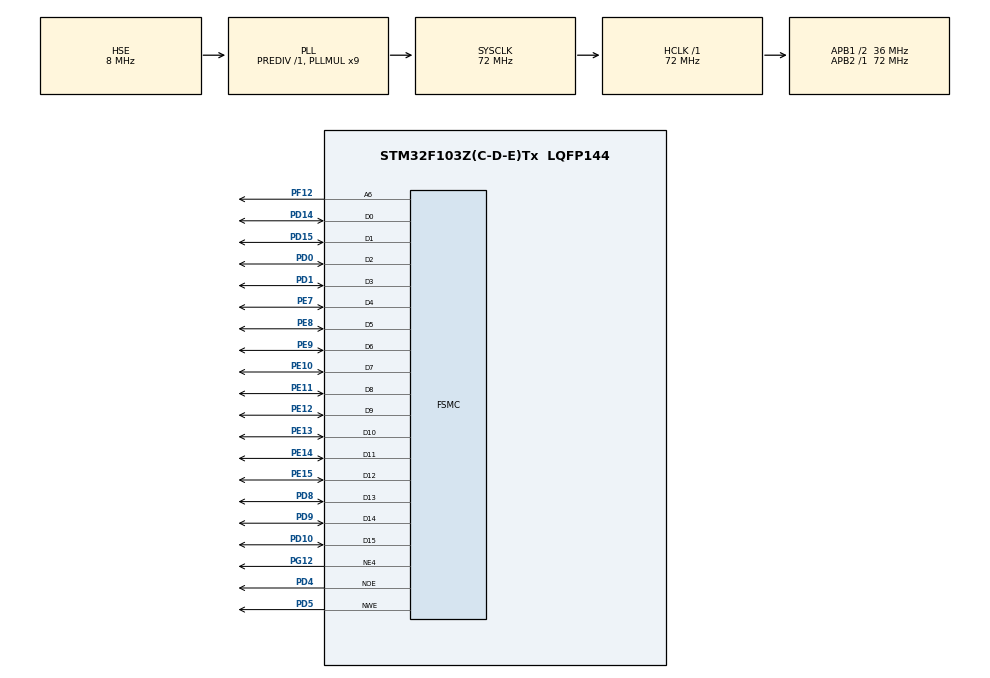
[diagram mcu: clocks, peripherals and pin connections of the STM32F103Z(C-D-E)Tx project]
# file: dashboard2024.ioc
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FREERTOS.Tasks01=defaultTask,24,128,StartDefaultTask,Default,NULL,Dynamic,NULL,NULL
FSMC.BusTurnAroundDuration4=0
FSMC.DataSetupTime4=60
FSMC.ExtendedAddressSetupTime4=9
FSMC.ExtendedBusTurnAroundDuration4=0
FSMC.ExtendedDataSetupTime4=8
FSMC.ExtendedMode4=FSMC_EXTENDED_MODE_ENABLE
Mcu.Family=STM32F1
Mcu.Name=STM32F103Z(C-D-E)Tx
Mcu.Package=LQFP144
NVIC.PriorityGroup=NVIC_PRIORITYGROUP_4
NVIC.TIM4_IRQn=true\:15\:0\:false\:false\:true\:false\:false\:true\:true
NVIC.TimeBase=TIM4_IRQn
NVIC.TimeBaseIP=TIM4
OSC_IN.Mode=HSE-External-Oscillator
OSC_IN.Signal=RCC_OSC_IN
OSC_OUT.Mode=HSE-External-Oscillator
OSC_OUT.Signal=RCC_OSC_OUT
PA13.Mode=Serial_Wire
PA13.Signal=SYS_JTMS-SWDIO
PA14.Mode=Serial_Wire
PA14.Signal=SYS_JTCK-SWCLK
PD0.Signal=FSMC_D2_DA2
PD1.Signal=FSMC_D3_DA3
PD10.Signal=FSMC_D15_DA15
PD14.Signal=FSMC_D0_DA0
PD15.Signal=FSMC_D1_DA1
PD4.Signal=FSMC_NOE
PD5.Signal=FSMC_NWE
PD8.Signal=FSMC_D13_DA13
PD9.Signal=FSMC_D14_DA14
PE10.Signal=FSMC_D7_DA7
PE11.Signal=FSMC_D8_DA8
PE12.Signal=FSMC_D9_DA9
PE13.Signal=FSMC_D10_DA10
PE14.Signal=FSMC_D11_DA11
PE15.Signal=FSMC_D12_DA12
PE7.Signal=FSMC_D4_DA4
PE8.Signal=FSMC_D5_DA5
PE9.Signal=FSMC_D6_DA6
PF12.Signal=FSMC_A6
PG12.Mode=NorPsramChipSelect4_4
PG12.Signal=FSMC_NE4
ProjectManager.HeapSize=0x200
ProjectManager.StackSize=0x400
ProjectManager.TargetToolchain=MDK-ARM V5.32
RCC.AHBFreq_Value=72000000
RCC.APB1CLKDivider=RCC_HCLK_DIV2
RCC.APB1Freq_Value=36000000
RCC.APB1TimFreq_Value=72000000
RCC.APB2Freq_Value=72000000
RCC.APB2TimFreq_Value=72000000
RCC.HCLKFreq_Value=72000000
RCC.PLLMUL=RCC_PLL_MUL9
RCC.PLLSourceVirtual=RCC_PLLSOURCE_HSE
RCC.SYSCLKFreq_VALUE=72000000
RCC.SYSCLKSource=RCC_SYSCLKSOURCE_PLLCLK
RCC.USBFreq_Value=72000000
SH.FSMC_A6.0=FSMC_A6,A6_4
SH.FSMC_D0_DA0.0=FSMC_D0,16b-d4
SH.FSMC_D10_DA10.0=FSMC_D10,16b-d4
SH.FSMC_D11_DA11.0=FSMC_D11,16b-d4
SH.FSMC_D12_DA12.0=FSMC_D12,16b-d4
SH.FSMC_D13_DA13.0=FSMC_D13,16b-d4
SH.FSMC_D14_DA14.0=FSMC_D14,16b-d4
SH.FSMC_D15_DA15.0=FSMC_D15,16b-d4
SH.FSMC_D1_DA1.0=FSMC_D1,16b-d4
SH.FSMC_D2_DA2.0=FSMC_D2,16b-d4
SH.FSMC_D3_DA3.0=FSMC_D3,16b-d4
SH.FSMC_D4_DA4.0=FSMC_D4,16b-d4
SH.FSMC_D5_DA5.0=FSMC_D5,16b-d4
SH.FSMC_D6_DA6.0=FSMC_D6,16b-d4
SH.FSMC_D7_DA7.0=FSMC_D7,16b-d4
SH.FSMC_D8_DA8.0=FSMC_D8,16b-d4
SH.FSMC_D9_DA9.0=FSMC_D9,16b-d4
SH.FSMC_NOE.0=FSMC_NOE,Lcd4
SH.FSMC_NWE.0=FSMC_NWE,Lcd4
VP_FREERTOS_VS_CMSIS_V2.Mode=CMSIS_V2
VP_SYS_VS_tim4.Mode=TIM4
board=custom

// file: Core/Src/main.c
/* USER CODE BEGIN Header */
/**
  ******************************************************************************
  * @file           : main.c
  * @brief          : Main program body
  ******************************************************************************
  * @attention
  *
  * Copyright (c) 2024 STMicroelectronics.
  * All rights reserved.
  *
  * This software is licensed under terms that can be found in the LICENSE file
  * in the root directory of this software component.
  * If no LICENSE file comes with this software, it is provided AS-IS.
  *
  ******************************************************************************
  */
/* USER CODE END Header */
#include "main.h"
#include "cmsis_os.h"
#include "gpio.h"
#include "fsmc.h"
#include"lcd.h"

/* USER CODE BEGIN PV */
// struct BMS_1860
// {

// }
/* USER CODE END PV */

void SystemClock_Config(void);
void MX_FREERTOS_Init(void);
void NewFunction();

/* USER CODE BEGIN 0 */
int Speed=-1;
int LCD_Speed=-1;

/* USER CODE END 0 */

int main(void)
{HAL_GPIO_TogglePin(GPIOB,10);
  /* USER CODE BHEGIN 1 */

  /* USER CODE END 1 */

  /* MCU Configuration--------------------------------------------------------*/

  /* Reset of all peripherals, Initializes the Flash interface and the Systick. */
  HAL_Init();

  /* Configure the system clock */
  SystemClock_Config();

  /* Initialize all configured peripherals */
  MX_GPIO_Init();
  MX_FSMC_Init();

  /* Init scheduler */
  osKernelInitialize();  /* Call init function for freertos objects (in freertos.c) */
  MX_FREERTOS_Init();

  /* Start scheduler */
  osKernelStart();

  /* We should never get here as control is now taken by the scheduler */
  /* Infinite loop */
  while (1)
  {

  }
}

void SystemClock_Config(void)
{
  RCC_OscInitTypeDef RCC_OscInitStruct = {0};
  RCC_ClkInitTypeDef RCC_ClkInitStruct = {0};

  /** Initializes the RCC Oscillators according to the specified parameters
  * in the RCC_OscInitTypeDef structure.
  */
  RCC_OscInitStruct.OscillatorType = RCC_OSCILLATORTYPE_HSE;
  RCC_OscInitStruct.HSEState = RCC_HSE_ON;
  RCC_OscInitStruct.HSEPredivValue = RCC_HSE_PREDIV_DIV1;
  RCC_OscInitStruct.HSIState = RCC_HSI_ON;
  RCC_OscInitStruct.PLL.PLLState = RCC_PLL_ON;
  RCC_OscInitStruct.PLL.PLLSource = RCC_PLLSOURCE_HSE;
  RCC_OscInitStruct.PLL.PLLMUL = RCC_PLL_MUL9;
  if (HAL_RCC_OscConfig(&RCC_OscInitStruct) != HAL_OK)
  {
    Error_Handler();
  }

  /** Initializes the CPU, AHB and APB buses clocks
  */
  RCC_ClkInitStruct.ClockType = RCC_CLOCKTYPE_HCLK|RCC_CLOCKTYPE_SYSCLK
                              |RCC_CLOCKTYPE_PCLK1|RCC_CLOCKTYPE_PCLK2;
  RCC_ClkInitStruct.SYSCLKSource = RCC_SYSCLKSOURCE_PLLCLK;
  RCC_ClkInitStruct.AHBCLKDivider = RCC_SYSCLK_DIV1;
  RCC_ClkInitStruct.APB1CLKDivider = RCC_HCLK_DIV2;
  RCC_ClkInitStruct.APB2CLKDivider = RCC_HCLK_DIV1;

  if (HAL_RCC_ClockConfig(&RCC_ClkInitStruct, FLASH_LATENCY_2) != HAL_OK)
  {
    Error_Handler();
  }
}

void HAL_TIM_PeriodElapsedCallback(TIM_HandleTypeDef *htim)
{
  if (htim->Instance == TIM4) {
    HAL_IncTick();
  }
}

void Error_Handler(void)
{
  __disable_irq();
  while (1)
  {
  }
}

//git 2024.9.18

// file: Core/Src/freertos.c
/* USER CODE BEGIN Header */
/**
  ******************************************************************************
  * File Name          : freertos.c
  * Description        : Code for freertos applications
  ******************************************************************************
  * @attention
  *
  * Copyright (c) 2024 STMicroelectronics.
  * All rights reserved.
  *
  * This software is licensed under terms that can be found in the LICENSE file
  * in the root directory of this software component.
  * If no LICENSE file comes with this software, it is provided AS-IS.
  *
  ******************************************************************************
  */
/* USER CODE END Header */

#include "FreeRTOS.h"
#include "task.h"
#include "main.h"
#include "cmsis_os.h"
#include"lcd.h"
/* USER CODE BEGIN Includes */
extern struct DisplayInfo Battary_Box_Voltag;
/* USER CODE END Includes */

/* Definitions for defaultTask */
osThreadId_t defaultTaskHandle;
const osThreadAttr_t defaultTask_attributes = {
  .name = "defaultTask",
  .stack_size = 128 * 4,
  .priority = (osPriority_t) osPriorityNormal,
};

/* USER CODE BEGIN FunctionPrototypes */
struct DisplayInfo Battary_Box_Voltage={26,10,"电池箱电压:",1};
struct DisplayInfo Cell_Temprature={646,10,"电芯温度:",1};
struct DisplayInfo HV_Board_Temprature={26,130,"高压板温度:",1};
struct DisplayInfo Main_Control_Temprature={42,250,"主控温度:",1};
struct DisplayInfo Battary_Box_Power={678,130,"功率:",1};
struct DisplayInfo Cell_Voltage={646,250,"电芯电压:",1};
struct DisplayInfo LV_Voltage={10,370,"低压电池电压:",1};
struct DisplayInfo Inverter_Temprature={328,370,"驱动器温度:",1};
struct DisplayInfo Motor_Temprature={646,370,"电机温度:",1};
struct DisplayInfo SOC={376,10,"SOC:",1};
// LCD_Show_Chinese_String(26,10,176,32,32,(u8*)"电池箱电压:");
// 	LCD_Show_Chinese_String(376,10,64,32,32,(u8*)"SOC:");
// 	LCD_Show_Chinese_String(646,10,144,32,32,"电芯温度:");

// 	LCD_Show_Chinese_String(26,130,176,32,32,"高压板温度:");
// 	LCD_Show_Chinese_String(42,250,144,32,32,"主控温度:");

// 	LCD_Show_Chinese_String(678,130,72,32,32,"功率:");
// 	LCD_Show_Chinese_String(646,250,144,32,32,"电芯电压:");

// 	LCD_Show_Chinese_String(10,370,208,32,32,"低压电池电压:");
// 	LCD_Show_Chinese_String(328,370,176,32,32,"驱动器温度:");
// 	LCD_Show_Chinese_String(646,370,144,32,32,"电机温度:");

void StartDefaultTask(void *argument);

void MX_FREERTOS_Init(void); /* (MISRA C 2004 rule 8.1) */

void MX_FREERTOS_Init(void) {
  /* USER CODE BEGIN Init */
TaskHandle_t  Battary_Box_VoltageHandle;
TaskHandle_t Cell_TempratureHandle;
TaskHandle_t HV_Board_TempratureHandle;
TaskHandle_t Main_Control_TempratureHandle;
TaskHandle_t Battary_Box_PowerHandle;
TaskHandle_t Cell_VoltageHandle;
TaskHandle_t LV_VoltageHandle;
TaskHandle_t Inverter_TempratureHandle;
TaskHandle_t SOCHandle;
TaskHandle_t Motor_TempratureHandle;
  /* USER CODE END Init */

  /* Create the thread(s) */
  /* creation of defaultTask */
  defaultTaskHandle = osThreadNew(StartDefaultTask, NULL, &defaultTask_attributes);

xTaskCreate(LCD_Print," Battary_Box_Voltage",128,&Battary_Box_Voltage,osPriorityNormal,&Battary_Box_VoltageHandle);
xTaskCreate(LCD_Print," Cell_Temprature",128,&Battary_Box_Voltage,osPriorityNormal,&Cell_TempratureHandle);
xTaskCreate(LCD_Print," HV_Board_Temprature",128,&Battary_Box_Voltage,osPriorityNormal,&HV_Board_TempratureHandle);
xTaskCreate(LCD_Print," Main_Control_Temprature",128,&Battary_Box_Voltage,osPriorityNormal,&Main_Control_TempratureHandle);
xTaskCreate(LCD_Print," Battary_Box_Power",128,&Battary_Box_Voltage,osPriorityNormal,&Battary_Box_PowerHandle);
xTaskCreate(LCD_Print," Cell_Voltage",128,&Battary_Box_Voltage,osPriorityNormal,&Cell_VoltageHandle);
xTaskCreate(LCD_Print," LV_Voltage",128,&Battary_Box_Voltage,osPriorityNormal,&LV_VoltageHandle);
xTaskCreate(LCD_Print," Inverter_Temprature",128,&Battary_Box_Voltage,osPriorityNormal,&Inverter_TempratureHandle);
xTaskCreate(LCD_Print," SOC",128,&Battary_Box_Voltage,osPriorityNormal,&SOCHandle);
xTaskCreate(LCD_Print," Motor_Temprature",128,&Battary_Box_Voltage,osPriorityNormal,&Motor_TempratureHandle);

}

void StartDefaultTask(void *argument)
{
  for(;;)
  {
    osDelay(1);
  }
}
